AUTOSAR XML (schema 4-3-1)
package /Components
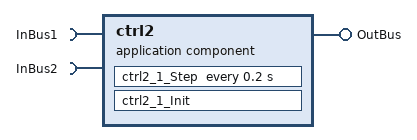
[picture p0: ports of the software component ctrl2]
  application sw component type ctrl2
    require port InBus1: nonqueued-receiver-com-spec{data-element=Value, init-value=0}, required-interface=InBus1
    require port InBus2: nonqueued-receiver-com-spec{data-element=Value, init-value=0}, required-interface=InBus2
    provide port OutBus: nonqueued-sender-com-spec{data-element=Value, init-value=0}, provided-interface=OutBus
    behavior ctrl2_1_IB: data-type-mapping=ctrl2DataTypeMappingsSet, handle-termination-and-restart=NO-SUPPORT
      timing event Event_ctrl2_1_Step: start-on-event=ctrl2_1_Step, period=0.2
      runnable ctrl2_1_Init
      runnable ctrl2_1_Step
        data-read-access:
          access IN_InBus1_Value: accessed-variable=InBus1.Value
          access IN_InBus2_Value: accessed-variable=InBus2.Value
        data-write-access:
          access OUT_OutBus_Value: accessed-variable=OutBus.Value
      shared-parameters:
        parameter data prototype my2d_LkupTbl: category=MAP, sw-calibration-access=READ-WRITE, type=Appl_my2d_LkupTbl, init-value=constant-reference={short-label=my2d_LkupTbl, constant=my2d_LkupTbl}
